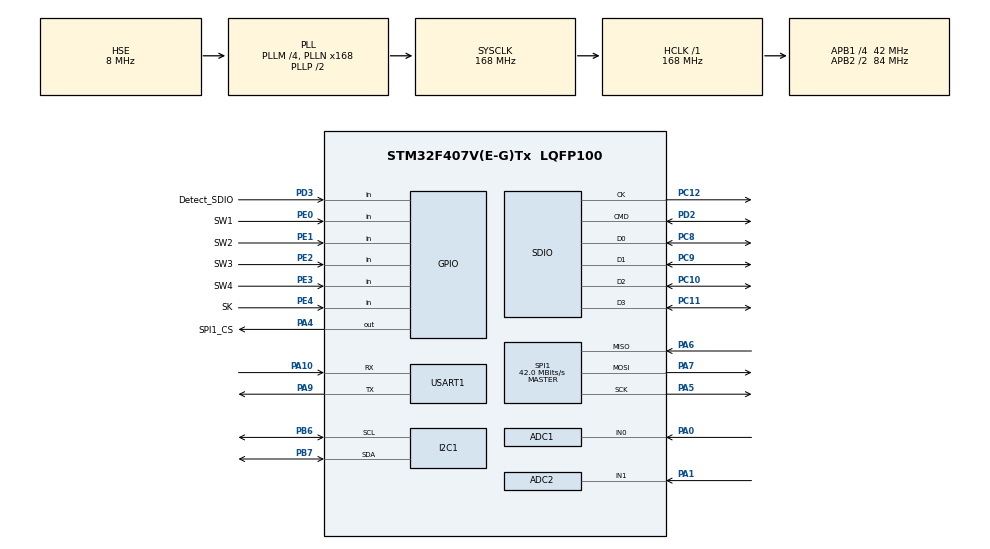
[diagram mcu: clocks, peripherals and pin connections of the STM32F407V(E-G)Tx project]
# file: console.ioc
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ADC1.Channel-0\#ChannelRegularConversion=ADC_CHANNEL_0
ADC1.ClockPrescaler=ADC_CLOCK_SYNC_PCLK_DIV4
ADC1.DMAContinuousRequests=ENABLE
ADC1.ExternalTrigConv=ADC_EXTERNALTRIGCONV_T3_TRGO
ADC1.InjNumberOfConversion=0
ADC1.Mode=ADC_DUALMODE_REGSIMULT
ADC1.NbrOfConversionFlag=1
ADC1.Rank-0\#ChannelRegularConversion=1
ADC1.SamplingTime-0\#ChannelRegularConversion=ADC_SAMPLETIME_56CYCLES
ADC1.ScanConvMode=ENABLE
ADC1.TwoSamplingDelay=ADC_TWOSAMPLINGDELAY_20CYCLES
ADC1.master=1
ADC2.Channel-0\#ChannelRegularConversion=ADC_CHANNEL_1
ADC2.ClockPrescaler=ADC_CLOCK_SYNC_PCLK_DIV4
ADC2.DMAContinuousRequests=ENABLE
ADC2.Mode=ADC_DUALMODE_REGSIMULT
ADC2.NbrOfConversionFlag=1
ADC2.Rank-0\#ChannelRegularConversion=1
ADC2.SamplingTime-0\#ChannelRegularConversion=ADC_SAMPLETIME_56CYCLES
ADC2.ScanConvMode=ENABLE
ADC2.TwoSamplingDelay=ADC_TWOSAMPLINGDELAY_20CYCLES
Dma.ADC1.0.Direction=DMA_PERIPH_TO_MEMORY
Dma.ADC1.0.FIFOMode=DMA_FIFOMODE_DISABLE
Dma.ADC1.0.Instance=DMA2_Stream0
Dma.ADC1.0.MemDataAlignment=DMA_MDATAALIGN_WORD
Dma.ADC1.0.MemInc=DMA_MINC_ENABLE
Dma.ADC1.0.Mode=DMA_CIRCULAR
Dma.ADC1.0.PeriphDataAlignment=DMA_PDATAALIGN_WORD
Dma.ADC1.0.PeriphInc=DMA_PINC_DISABLE
Dma.ADC1.0.Priority=DMA_PRIORITY_LOW
Dma.ADC2.1.Direction=DMA_PERIPH_TO_MEMORY
Dma.ADC2.1.FIFOMode=DMA_FIFOMODE_DISABLE
Dma.ADC2.1.Instance=DMA2_Stream2
Dma.ADC2.1.MemDataAlignment=DMA_MDATAALIGN_WORD
Dma.ADC2.1.MemInc=DMA_MINC_ENABLE
Dma.ADC2.1.Mode=DMA_CIRCULAR
Dma.ADC2.1.PeriphDataAlignment=DMA_PDATAALIGN_WORD
Dma.ADC2.1.PeriphInc=DMA_PINC_DISABLE
Dma.ADC2.1.Priority=DMA_PRIORITY_LOW
Dma.Request0=ADC1
Dma.Request1=ADC2
Dma.Request2=SDIO
Dma.SDIO.2.Direction=DMA_PERIPH_TO_MEMORY
Dma.SDIO.2.FIFOMode=DMA_FIFOMODE_ENABLE
Dma.SDIO.2.FIFOThreshold=DMA_FIFO_THRESHOLD_FULL
Dma.SDIO.2.Instance=DMA2_Stream3
Dma.SDIO.2.MemBurst=DMA_MBURST_INC4
Dma.SDIO.2.MemDataAlignment=DMA_MDATAALIGN_WORD
Dma.SDIO.2.MemInc=DMA_MINC_ENABLE
Dma.SDIO.2.Mode=DMA_PFCTRL
Dma.SDIO.2.PeriphBurst=DMA_PBURST_INC4
Dma.SDIO.2.PeriphDataAlignment=DMA_PDATAALIGN_WORD
Dma.SDIO.2.PeriphInc=DMA_PINC_DISABLE
Dma.SDIO.2.Priority=DMA_PRIORITY_LOW
FATFS.BSP.number=1
FATFS._CODE_PAGE=936
FATFS._USE_LFN=3
FATFS0.BSP.STBoard=false
FATFS0.BSP.api=Unknown
FATFS0.BSP.instance=PD3
FATFS0.BSP.ip=GPIO
FATFS0.BSP.mode=Input
FATFS0.BSP.name=Detect_SDIO
FATFS0.BSP.solution=PD3
I2C1.I2C_Mode=I2C_Fast
Mcu.Family=STM32F4
Mcu.Name=STM32F407V(E-G)Tx
Mcu.Package=LQFP100
NVIC.ADC_IRQn=true\:0\:0\:false\:false\:true\:true\:true\:true
NVIC.DMA2_Stream0_IRQn=true\:0\:0\:false\:false\:true\:false\:true\:true
NVIC.DMA2_Stream2_IRQn=true\:0\:0\:false\:false\:true\:false\:true\:true
NVIC.DMA2_Stream3_IRQn=true\:0\:0\:false\:false\:true\:false\:true\:true
NVIC.PriorityGroup=NVIC_PRIORITYGROUP_4
NVIC.USART1_IRQn=true\:0\:0\:false\:false\:true\:true\:true\:true
PA0-WKUP.Signal=ADCx_IN0
PA1.Signal=ADCx_IN1
PA10.Mode=Asynchronous
PA10.Signal=USART1_RX
PA13.Mode=Serial_Wire
PA13.Signal=SYS_JTMS-SWDIO
PA14.Mode=Serial_Wire
PA14.Signal=SYS_JTCK-SWCLK
PA4.GPIO_Label=SPI1_CS
PA4.GPIO_Speed=GPIO_SPEED_FREQ_HIGH
PA4.PinState=GPIO_PIN_SET
PA4.Signal=GPIO_Output
PA5.Mode=Full_Duplex_Master
PA5.Signal=SPI1_SCK
PA6.Mode=Full_Duplex_Master
PA6.Signal=SPI1_MISO
PA7.Mode=Full_Duplex_Master
PA7.Signal=SPI1_MOSI
PA9.Mode=Asynchronous
PA9.Signal=USART1_TX
PB6.Mode=I2C
PB6.Signal=I2C1_SCL
PB7.Mode=I2C
PB7.Signal=I2C1_SDA
PC10.Mode=SD_4_bits_Wide_bus
PC10.Signal=SDIO_D2
PC11.Mode=SD_4_bits_Wide_bus
PC11.Signal=SDIO_D3
PC12.Mode=SD_4_bits_Wide_bus
PC12.Signal=SDIO_CK
PC14-OSC32_IN.Mode=LSE-External-Oscillator
PC14-OSC32_IN.Signal=RCC_OSC32_IN
PC15-OSC32_OUT.Mode=LSE-External-Oscillator
PC15-OSC32_OUT.Signal=RCC_OSC32_OUT
PC8.Mode=SD_4_bits_Wide_bus
PC8.Signal=SDIO_D0
PC9.Mode=SD_4_bits_Wide_bus
PC9.Signal=SDIO_D1
PD2.Mode=SD_4_bits_Wide_bus
PD2.Signal=SDIO_CMD
PD3.GPIO_Label=Detect_SDIO
PD3.Signal=GPIO_Input
PE0.GPIO_Label=SW1
PE0.Signal=GPIO_Input
PE1.GPIO_Label=SW2
PE1.Signal=GPIO_Input
PE2.GPIO_Label=SW3
PE2.Signal=GPIO_Input
PE3.GPIO_Label=SW4
PE3.Signal=GPIO_Input
PE4.GPIO_Label=SK
PE4.Signal=GPIO_Input
PH0-OSC_IN.Mode=HSE-External-Oscillator
PH0-OSC_IN.Signal=RCC_OSC_IN
PH1-OSC_OUT.Mode=HSE-External-Oscillator
PH1-OSC_OUT.Signal=RCC_OSC_OUT
ProjectManager.HeapSize=0x2000
ProjectManager.StackSize=0x4000
ProjectManager.TargetToolchain=MDK-ARM V5
RCC.48MHZClocksFreq_Value=48000000
RCC.AHBFreq_Value=168000000
RCC.APB1CLKDivider=RCC_HCLK_DIV4
RCC.APB1Freq_Value=42000000
RCC.APB1TimFreq_Value=84000000
RCC.APB2CLKDivider=RCC_HCLK_DIV2
RCC.APB2Freq_Value=84000000
RCC.APB2TimFreq_Value=168000000
RCC.CortexFreq_Value=168000000
RCC.HCLKFreq_Value=168000000
RCC.HSE_VALUE=8000000
RCC.HSI_VALUE=16000000
RCC.PLLM=4
RCC.PLLN=168
RCC.PLLQ=7
RCC.PLLSourceVirtual=RCC_PLLSOURCE_HSE
RCC.SYSCLKFreq_VALUE=168000000
RCC.SYSCLKSource=RCC_SYSCLKSOURCE_PLLCLK
RCC.VCOOutputFreq_Value=336000000
SDIO.ClockDiv=2
SH.ADCx_IN0.0=ADC1_IN0,IN0
SH.ADCx_IN1.0=ADC2_IN1,IN1
SPI1.CLKPhase=SPI_PHASE_1EDGE
SPI1.CLKPolarity=SPI_POLARITY_LOW
SPI1.CalculateBaudRate=42.0 MBits/s
SPI1.Direction=SPI_DIRECTION_2LINES
SPI1.Mode=SPI_MODE_MASTER
SPI1.VirtualType=VM_MASTER
TIM3.Period=10 - 1
TIM3.Prescaler=840 - 1
TIM3.TIM_MasterOutputTrigger=TIM_TRGO_UPDATE
USART1.VirtualMode=VM_ASYNC
VP_FATFS_VS_SDIO.Mode=SDIO
VP_RNG_VS_RNG.Mode=RNG_Activate
VP_TIM3_VS_ClockSourceINT.Mode=Internal
board=custom

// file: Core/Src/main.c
/* USER CODE BEGIN Header */
/**
  ******************************************************************************
  * @file           : main.c
  * @brief          : Main program body
  ******************************************************************************
  * @attention
  *
  * Copyright (c) 2025 STMicroelectronics.
  * All rights reserved.
  *
  * This software is licensed under terms that can be found in the LICENSE file
  * in the root directory of this software component.
  * If no LICENSE file comes with this software, it is provided AS-IS.
  *
  ******************************************************************************
  */
/* USER CODE END Header */
#include "main.h"
#include "adc.h"
#include "dma.h"
#include "fatfs.h"
#include "i2c.h"
#include "rng.h"
#include "sdio.h"
#include "spi.h"
#include "tim.h"
#include "usart.h"
#include "gpio.h"

/* USER CODE BEGIN Includes */
#include "mydefine.h"
/* USER CODE END Includes */

void SystemClock_Config(void);

int main(void)
{

  /* MCU Configuration--------------------------------------------------------*/

  /* Reset of all peripherals, Initializes the Flash interface and the Systick. */
  HAL_Init();

  /* Configure the system clock */
  SystemClock_Config();

  /* Initialize all configured peripherals */
  MX_GPIO_Init();
  MX_DMA_Init();
  MX_USART1_UART_Init();
  MX_ADC1_Init();
  MX_ADC2_Init();
  MX_TIM3_Init();
  MX_I2C1_Init();
  MX_RNG_Init();
  MX_SPI1_Init();
  MX_SDIO_SD_Init();
  MX_FATFS_Init();
  /* USER CODE BEGIN 2 */
	// 1. 系统装配初始化：调用驱动、组件、事件队列等的初始化函数
  system_assembly_init();

	// 2. 任务注册：将所有应用层任务注册到调度器中
  system_assembly_register_tasks();
  /* USER CODE END 2 */

  /* Infinite loop */
  while (1)
  {

    /* USER CODE BEGIN 3 */
		scheduler_run();
  }
  /* USER CODE END 3 */
}

void SystemClock_Config(void)
{
  RCC_OscInitTypeDef RCC_OscInitStruct = {0};
  RCC_ClkInitTypeDef RCC_ClkInitStruct = {0};

  /** Configure the main internal regulator output voltage
  */
  __HAL_RCC_PWR_CLK_ENABLE();
  __HAL_PWR_VOLTAGESCALING_CONFIG(PWR_REGULATOR_VOLTAGE_SCALE1);

  /** Initializes the RCC Oscillators according to the specified parameters
  * in the RCC_OscInitTypeDef structure.
  */
  RCC_OscInitStruct.OscillatorType = RCC_OSCILLATORTYPE_HSE;
  RCC_OscInitStruct.HSEState = RCC_HSE_ON;
  RCC_OscInitStruct.PLL.PLLState = RCC_PLL_ON;
  RCC_OscInitStruct.PLL.PLLSource = RCC_PLLSOURCE_HSE;
  RCC_OscInitStruct.PLL.PLLM = 4;
  RCC_OscInitStruct.PLL.PLLN = 168;
  RCC_OscInitStruct.PLL.PLLP = RCC_PLLP_DIV2;
  RCC_OscInitStruct.PLL.PLLQ = 7;
  if (HAL_RCC_OscConfig(&RCC_OscInitStruct) != HAL_OK)
  {
    Error_Handler();
  }

  /** Initializes the CPU, AHB and APB buses clocks
  */
  RCC_ClkInitStruct.ClockType = RCC_CLOCKTYPE_HCLK|RCC_CLOCKTYPE_SYSCLK
                              |RCC_CLOCKTYPE_PCLK1|RCC_CLOCKTYPE_PCLK2;
  RCC_ClkInitStruct.SYSCLKSource = RCC_SYSCLKSOURCE_PLLCLK;
  RCC_ClkInitStruct.AHBCLKDivider = RCC_SYSCLK_DIV1;
  RCC_ClkInitStruct.APB1CLKDivider = RCC_HCLK_DIV4;
  RCC_ClkInitStruct.APB2CLKDivider = RCC_HCLK_DIV2;

  if (HAL_RCC_ClockConfig(&RCC_ClkInitStruct, FLASH_LATENCY_5) != HAL_OK)
  {
    Error_Handler();
  }
}

void Error_Handler(void)
{
  __disable_irq();
  while (1)
  {
  }
}
